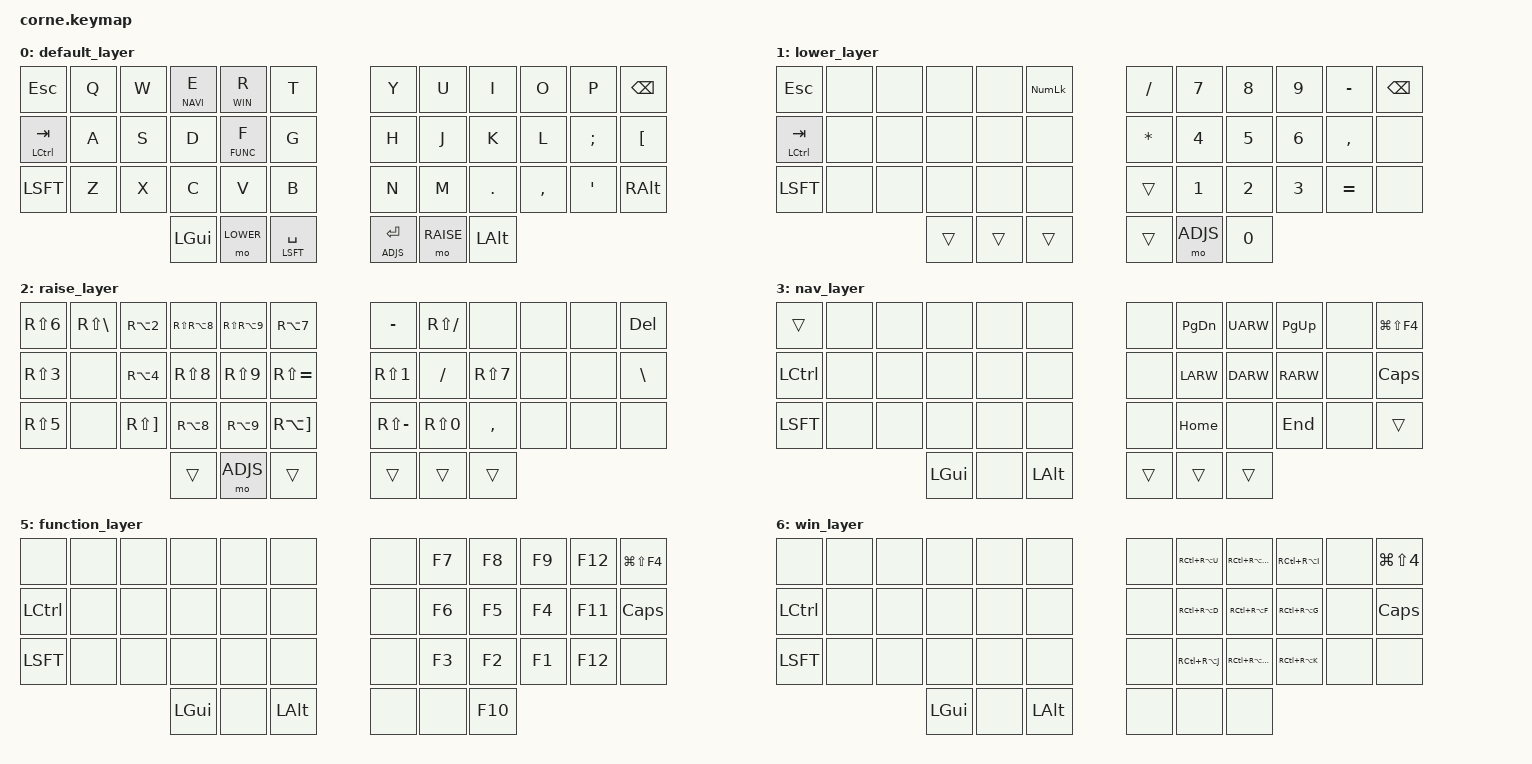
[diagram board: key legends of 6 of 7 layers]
/*
 * Copyright (c) 2020 The ZMK Contributors
 *
 * SPDX-License-Identifier: MIT
 */

#include <behaviors.dtsi>
#include <dt-bindings/zmk/keys.h>
#include <dt-bindings/zmk/bt.h>
#include <dt-bindings/zmk/ext_power.h>
#include <dt-bindings/zmk/rgb.h>

// defines readable layer index
#define DEFAULT 0
#define LOWER   1
#define RAISE   2
#define NAVI    3
#define ADJS    4
#define FUNC    5
#define WIN     6

/ {
        keymap {
                compatible = "zmk,keymap";

                default_layer { 
// DEFAULT LAYER
// .--------------------------------------------------------------.       .-----------------------------------------------------------.
// |   ESC        |    Q    |    W   |  E/NAV | R/WIN   |    T    |       |   Y   |    U    |    I    |    O    |     P    |   BKSP   |
// |--------------+---------+--------+--------+---------+---------|       |-------+---------+---------+---------+----------+----------|
// |   CTRL/Tab   |    A    |    S   |   D    | F/FUNC  |    G    |       |   H   |    J    |    K    |    L    |     Ö    |     Ä    |
// |--------------+---------+--------+--------+---------+---------|       |-------+---------+---------+---------+----------+----------|
// |   SHFT       |    Z    |    X   |   C    |    V    |    B    |       |   N   |    M    |    .    |    ,    |     Å    |     NAV  |
// '---------------------------------+--------+---------+---------+       |-------+---------+---------+-------------------------------'
//                                   |  GUI   |   RSE   |   SPC   |       |  ENT  |   LWR   |  LALT   |
//                                   '--------+---------+---------'       '-------+---------+---------'
                  bindings = <
        &kp ESC        &kp Q    &kp W    &lt NAVI E  &lt WIN R     &kp T           &kp Y    &kp U      &kp I     &kp O     &kp P     &kp BKSP
        &mt LCTL TAB   &kp A    &kp S    &kp D    &lt FUNC F   &kp G           &kp H    &kp J      &kp K     &kp L     &kp SCLN  &kp LBKT
        &kp LSFT       &kp Z    &kp X    &kp C    &kp V        &kp B           &kp N    &kp M      &kp DOT   &kp CMMA  &kp QUOT  &kp RALT
                                       &kp LGUI  &mo LOWER     &mt LSFT SPC    &mt ADJS RET  &mo RAISE  &kp LALT
                            >;
                };


                lower_layer {
// LOWER Layer: Media and Number Pad
// .--------------------------------------------------------------.    .-----------------------------------------------------------.
// |     ESC      |         |        |        |         | Numlock |    |  / ?  |   7 &   |   8 *   |   9 (   |   - _    |   BKSP   |
// |--------------+---------+--------+--------+---------+---------|    |-------+---------+---------+---------+----------+----------|
// |  CTRL/Tab    |         |        |        |         |         |    |   *   |   4 $   |   5 %   |   6 ^   |   , <    |          |
// |--------------+---------+--------+--------+---------+---------|    |-------+---------+---------+---------+----------+----------|
// |  SHIFT       |         |        |        |         |         |    |       |   1 !   |   2 @   |   3 #   |   = +    |          |
// '---------------------------------+--------+---------+---------+    |-------+---------+---------+-------------------------------'
//                                   |        |         |         |    |       |         |    0 )  |
//                                   '--------+---------+---------'    '-------+---------+---------'

                  bindings = <
          &kp ESC          &none   &none   &none   &none   &kp KP_NUMLOCK      &kp FSLH   &kp NUM_7  &kp NUM_8  &kp NUM_9  &kp MINUS  &kp BKSP
          &mt LCTL TAB     &none   &none   &none   &none   &none       &kp STAR   &kp NUM_4  &kp NUM_5  &kp NUM_6  &kp COMMA  &none
          &kp LSFT         &none   &none   &none   &none   &none       &trans     &kp NUM_1  &kp NUM_2  &kp NUM_3  &kp EQUAL  &none
                                           &trans  &trans  &trans      &trans     &mo ADJS   &kp NUM_0
                            >;
                };



                raise_layer {
// RAISE Layer: Special Chars
// .--------------------------------------------------------------.    .-----------------------------------------------------------.
// |       &      |   *     |    @   |   {    |    }    |    |    |    |   +   |    -    |    €    |         |          |   DEL    |
// |--------------+---------+--------+--------+---------+---------|    |-------+---------+---------+---------+----------+----------|
// |       #      |         |    $   |   (    |    )    |    `    |    |   !   |    _    |    /    |         |          |     '    |
// |--------------+---------+--------+--------+---------+---------|    |-------+---------+---------+---------+----------+----------|
// |       %      |         |    ^   |   [    |    ]    |    ~    |    |   ?   |    =    |    ,    |         |          |          |
// '---------------------------------+--------+---------+---------+    |-------+---------+---------+-------------------------------'
//                                   |        |         |         |    |       |         |         |
//                                   '--------+---------+---------'    '-------+---------+---------'
                        bindings = <
        &kp RS(N6) &kp RS(BSLH)   &kp RA(N2)    &kp RS(RA(N8))  &kp RS(RA(N9))  &kp RA(N7)  &kp MINUS     &kp RS(FSLH)  &none  &none  &none  &kp DEL
        &kp RS(N3) &none   &kp RA(N4)    &kp RS(N8)      &kp RS(N9)  &kp RS(EQUAL)          &kp RS(N1)     &kp FSLH   &kp RS(N7)   &none  &none  &kp BSLH
        &kp RS(N5) &none   &kp RS(RBKT) &kp RA(N8)      &kp RA(N9)  &kp RA(RBKT)            &kp RS(MINUS)    &kp RS(N0)     &kp COMMA  &none  &none  &none
                                      &trans    &mo ADJS  &trans                            &trans        &trans     &trans
                        >;
                };


              nav_layer {
// NAVIGATION Layer: Directions
// .--------------------------------------------------------------.    .-----------------------------------------------------------.
// |              |         |        |        |         |         |    |       |  PG DN  |   UP    |  PG UP  |          |  PrtScn  |
// |--------------+---------+--------+--------+---------+---------|    |-------+---------+---------+---------+----------+----------|
// |     CTRL     |         |        |        |         |         |    |       |  LEFT   |  DOWN   |  RIGHT  |          | CAPS LCK |
// |--------------+---------+--------+--------+---------+---------|    |-------+---------+---------+---------+----------+----------|
// |     SHIFT    |         |        |        |         |         |    |       | PG HOME |         | PG END  |          |          |
// '---------------------------------+--------+---------+---------+    |-------+---------+---------+-------------------------------'
//                                   |  GUI   |         |   ALT   |    |       |         |         |
//                                   '--------+---------+---------'    '-------+---------+---------'
                        bindings = <
          &trans     &none   &none    &none     &none    &none           &none      &kp PG_DN  &kp UARW   &kp PG_UP   &none  &kp LG(LS(F4))
          &kp LCTL  &none   &none    &none     &none    &none           &none      &kp LARW   &kp DARW   &kp RARW  &none  &kp CLCK
          &kp LSFT  &none   &none    &none     &none    &none           &none      &kp HOME   &none      &kp END     &none  &trans
                                     &kp LGUI  &none    &kp LALT        &trans     &trans    &trans
                        >;
                };


                adjust_layer {
// ADJUST Layer: Setting and Configurations
// .------------------------------------------------------------.    .-------------------------------------------------------------.
// |      0     |  BT 0   |  BT 1  |  BT 2  |  BT 3   |  BT 4   |    |  BT CLR |         |         |         | Bright Up|  Vol up  |
// |------------+---------+--------+--------+---------+---------|    |---------+---------+---------+---------+----------+----------|
// | ExtPow ON  | RGB_TOG | RGB_EFR| HUE UP | RGB_SAI |         |    |         |         |         |         | Bright Dn|  Vol dn  |
// |------------+---------+--------+--------+---------+---------|    |---------+---------+---------+---------+----------+----------|
// | ExtPow OFF |         | RGB_EFF| HUE DN | RGB_SAD |         |    |         |         |         |         |          |  Mute    |
// '-------------------------------+--------+---------+---------+    |---------+---------+---------+-------------------------------'
//                                 |        |         |         |    |         |         |         |
//                                 '--------+---------+---------'    '---------+---------+---------'

                        bindings = <
    &kp NUM_0           &bt BT_SEL 0         &bt BT_SEL 1       &bt BT_SEL 2            &bt BT_SEL 3            &bt BT_SEL 4   &bt BT_CLR  &ext_power EP_ON  &ext_power EP_OFF  &none      &kp C_BRI_UP    &kp C_VOL_UP
    &ext_power EP_ON    &rgb_ug RGB_TOG      &rgb_ug RGB_EFR    &rgb_ug RGB_HUI         &rgb_ug RGB_SAI         &rgb_ug RGB_TOG      &rgb_ug RGB_EFR    &rgb_ug RGB_HUI         &rgb_ug RGB_SAI      &kp C_BRI_DN    &kp C_VOL_DN
    &ext_power EP_OFF   &none                &rgb_ug RGB_EFF    &rgb_ug RGB_HUD         &rgb_ug RGB_SAD         &rgb_ug RGB_EFF    &rgb_ug RGB_HUD         &rgb_ug RGB_SAD              &kp K_MUTE
                                                                      &kp LALT      &none         &none                       &none       &none      &none
                        >;
                };


              function_layer {
// Function Layer: Functionality
// .--------------------------------------------------------------.    .-----------------------------------------------------------.
// |              |         |        |        |         |         |    |       |  F7     |  F8     |  F9     |  F12     |  PrtScn  |
// |--------------+---------+--------+--------+---------+---------|    |-------+---------+---------+---------+----------+----------|
// |     CTRL     |         |        |        |         |         |    |       |  F6     |  F5     |  F4     |  F11     | CAPS LCK |
// |--------------+---------+--------+--------+---------+---------|    |-------+---------+---------+---------+----------+----------|
// |     SHIFT    |         |        |        |         |         |    |       |  F3     |  F2     |  F1     |          |          |
// '---------------------------------+--------+---------+---------+    |-------+---------+---------+-------------------------------'
//                                   |  GUI   |         |   ALT   |    |       |         |  F10    |
//                                   '--------+---------+---------'    '-------+---------+---------'
                        bindings = <
          &none     &none   &none    &none     &none    &none           &none      &kp F7   &kp F8   &kp F9   &kp F12   &kp LG(LS(F4))
          &kp LCTL  &none   &none    &none     &none    &none           &none      &kp F6   &kp F5   &kp F4   &kp F11   &kp CLCK
          &kp LSFT  &none   &none    &none     &none    &none           &none      &kp F3   &kp F2   &kp F1   &kp F12   &none
                                     &kp LGUI  &none    &kp LALT        &none      &none    &kp F10
                        >;
                };
                
                              win_layer {
// Window Layer: Windows
// .--------------------------------------------------------------.    .-----------------------------------------------------------.
// |              |         |        |        |         |         |    |       |  UL     |  UM     |  UR     |  F12     |  PrtScn  |
// |--------------+---------+--------+--------+---------+---------|    |-------+---------+---------+---------+----------+----------|
// |     CTRL     |         |        |        |         |         |    |       |  ML     |  MM     |  MR     |  F11     | CAPS LCK |
// |--------------+---------+--------+--------+---------+---------|    |-------+---------+---------+---------+----------+----------|
// |     SHIFT    |         |        |        |         |         |    |       |  BL     |  ML     |  MR     |          |          |
// '---------------------------------+--------+---------+---------+    |-------+---------+---------+-------------------------------'
//                                   |  GUI   |         |   ALT   |    |       |         |  F10    |
//                                   '--------+---------+---------'    '-------+---------+---------'
                        bindings = <
          &none     &none   &none    &none     &none    &none           &none      &kp RC(RA(U))   &kp RC(RA(UARW))   &kp RC(RA(I))   &none   &kp LG(LS(N4))
          &kp LCTL  &none   &none    &none     &none    &none           &none      &kp RC(RA(D))   &kp RC(RA(F))      &kp RC(RA(G))   &none   &kp CLCK
          &kp LSFT  &none   &none    &none     &none    &none           &none      &kp RC(RA(J))   &kp RC(RA(DARW))   &kp RC(RA(K))   &none   &none
                                     &kp LGUI  &none    &kp LALT        &none      &none           &none
                        >;
                };


                
        };
};
